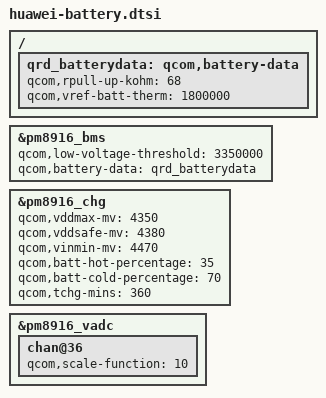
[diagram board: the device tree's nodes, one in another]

/ {
	qrd_batterydata: qcom,battery-data {
		qcom,rpull-up-kohm = <68>;
		qcom,vref-batt-therm = <1800000>;
                #include "HB474284RBC_BYD_BYD-4v35-2000mah.dtsi"
                #include "HB474284RBC_LG_SCUD-4v35-2000mah.dtsi"
	};
};

&pm8916_bms {
	status = "ok";
	qcom,low-voltage-threshold = <3350000>;
	qcom,battery-data = <&qrd_batterydata>;
};

&pm8916_chg {
	status = "okay";
	qcom,vddmax-mv = <4350>;
	qcom,vddsafe-mv = <4380>;
	qcom,vinmin-mv = <4470>;
	qcom,batt-hot-percentage = <35>;
	qcom,batt-cold-percentage = <70>;
	qcom,tchg-mins = <360>;
};

&pm8916_vadc {
	chan@36 {
		qcom,scale-function = <10>;
	};
};

